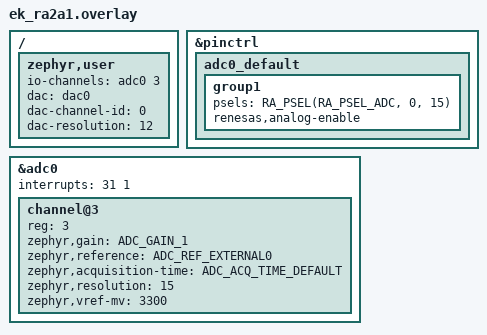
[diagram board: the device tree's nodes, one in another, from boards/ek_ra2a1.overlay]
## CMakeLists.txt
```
# SPDX-License-Identifier: Apache-2.0

cmake_minimum_required(VERSION 3.28.0)

find_package(Zephyr REQUIRED HINTS $ENV{ZEPHYR_BASE})
project(adc_accuracy)

target_sources(app PRIVATE src/main.c)
target_sources_ifdef(CONFIG_REFERENCE_VOLTAGE_TEST app PRIVATE src/ref_volt.c)
target_sources_ifdef(CONFIG_DAC_SOURCE_TEST app PRIVATE src/dac_source.c)
```

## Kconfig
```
# Copyright (c) 2023 Intel Corporation
# Copyright (c) 2025 Renesas Electronics Corporation
#
# SPDX-License-Identifier: Apache-2.0

mainmenu "ADC accuracy test"

source "Kconfig.zephyr"

# Workaround to have commas on function arguments
ZEPHYR_USER := zephyr,user

config DAC_SOURCE_TEST
	bool "Test using a DAC source"
	select DAC
	depends on $(dt_node_has_prop,/$(ZEPHYR_USER),dac)
	depends on $(dt_node_has_prop,/$(ZEPHYR_USER),dac-channel-id)
	depends on $(dt_node_has_prop,/$(ZEPHYR_USER),dac-resolution)

config REFERENCE_VOLTAGE_TEST
	bool "Test using a ref voltage source"
	depends on $(dt_node_has_prop,/$(ZEPHYR_USER),reference-mv)
	depends on $(dt_node_has_prop,/$(ZEPHYR_USER),expected-accuracy)

config NUMBER_OF_PASSES
	int "Number of passes"
	default 5

config TEST_ADC_CALIBRATE_REQUIRED
	bool "Require calibrate field in ADC test"
	default y if DT_HAS_RENESAS_RA_ADC16_ENABLED

if DAC_SOURCE_TEST

config DAC_BUFFER_NOT_SUPPORTED
	bool "DAC on board/SoC does not support output buffer mode"
	help
	  If this config is selected, the test will run with no output buffer enabled

endif # DAC_SOURCE_TEST
```

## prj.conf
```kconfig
CONFIG_ZTEST=y
CONFIG_ADC=y
```

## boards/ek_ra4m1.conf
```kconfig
# Copyright (c) 2025 Renesas Electronics Corporation
# SPDX-License-Identifier: Apache-2.0

CONFIG_DAC_BUFFER_NOT_SUPPORTED=y
```

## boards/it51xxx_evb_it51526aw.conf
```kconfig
# Copyright (c) 2026 ITE Corporation. All Rights Reserved.
# SPDX-License-Identifier: Apache-2.0

CONFIG_REFERENCE_VOLTAGE_TEST=y
```

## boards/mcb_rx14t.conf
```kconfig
CONFIG_REFERENCE_VOLTAGE_TEST=y
```

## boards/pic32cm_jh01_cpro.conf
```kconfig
#SPDX-FileCopyrightText: Copyright (c) 2026 Microchip Technology Inc.
#SPDX-License-Identifier: Apache-2.0

CONFIG_DAC=y
CONFIG_DAC_BUFFER_NOT_SUPPORTED=y
```

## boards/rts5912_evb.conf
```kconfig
# RTS5912 EVB ADC Accuracy Test Configuration
# Enable reference voltage test mode (using potentiometer as voltage source)
CONFIG_REFERENCE_VOLTAGE_TEST=y
```

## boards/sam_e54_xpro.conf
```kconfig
# Copyright (c) 2026 Microchip Technology Inc.
# SPDX-License-Identifier: Apache-2.0

CONFIG_DAC=y
CONFIG_DAC_BUFFER_NOT_SUPPORTED=y
```

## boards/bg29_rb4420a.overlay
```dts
/*
 * Copyright (c) 2025 Silicon Laboratories Inc.
 *
 * SPDX-License-Identifier: Apache-2.0
 */

#include "dt-bindings/adc/silabs-adc.h"

/ {
	zephyr,user {
		io-channels = <&adc0 4>;
		reference-mv = <(1500 / 4)>;
		expected-accuracy = <32>;
	};
};

&adc0 {
	#address-cells = <1>;
	#size-cells = <0>;
	status = "okay";

	channel@4 {
		reg = <4>;
		zephyr,gain = "ADC_GAIN_1";
		zephyr,reference = "ADC_REF_INTERNAL";
		zephyr,acquisition-time = <ADC_ACQ_TIME_DEFAULT>;
		zephyr,resolution = <12>;
		zephyr,input-positive = <IADC_INPUT_VBAT>;
	};
};
```

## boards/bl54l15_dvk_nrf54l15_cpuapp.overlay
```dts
/*
 * SPDX-License-Identifier: Apache-2.0
 *
 * Copyright (c) 2024 Nordic Semiconductor ASA
 * Copyright (c) 2025 Ezurio LLC
 */

/ {
	zephyr,user {
		io-channels = <&adc 0>;
		reference-mv = <1800>;
		expected-accuracy = <64>;
	};
};

&adc {
	#address-cells = <1>;
	#size-cells = <0>;

	channel@0 {
		reg = <0>;
		zephyr,gain = "ADC_GAIN_1_2";
		zephyr,reference = "ADC_REF_INTERNAL";
		zephyr,acquisition-time = <ADC_ACQ_TIME_DEFAULT>;
		zephyr,input-positive = <NRF_SAADC_AIN2>;
		zephyr,resolution = <14>;
	};
};
```

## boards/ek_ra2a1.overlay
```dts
/*
 * Copyright (c) 2024-2025 Renesas Electronics Corporation
 *
 * SPDX-License-Identifier: Apache-2.0
 */

/ {
	zephyr,user {
		io-channels = <&adc0 3>;
		dac = <&dac0>;
		dac-channel-id = <0>;
		dac-resolution = <12>;
	};
};

&pinctrl {
	adc0_default: adc0_default {
		group1 {
			/* input */
			psels = <RA_PSEL(RA_PSEL_ADC, 0, 15)>;
			renesas,analog-enable;
		};
	};
};

&adc0 {
	#address-cells = <1>;
	#size-cells = <0>;
	interrupts = <31 1>;
	interrupt-names = "scanend";
	status = "okay";

	/*
	 * Channel 3 is used in single ended mode, with 15 bit resolution
	 */
	channel@3 {
		reg = <3>;
		zephyr,gain = "ADC_GAIN_1";
		zephyr,reference = "ADC_REF_EXTERNAL0";
		zephyr,acquisition-time = <ADC_ACQ_TIME_DEFAULT>;
		zephyr,resolution = <15>;
		zephyr,vref-mv = <3300>;
	};
};
```

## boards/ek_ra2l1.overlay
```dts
/*
 * Copyright (c) 2025 Renesas Electronics Corporation
 *
 * SPDX-License-Identifier: Apache-2.0
 */

/ {
	zephyr,user {
		io-channels = <&adc0 0>;
		dac = <&dac0>;
		dac-channel-id = <0>;
		dac-resolution = <12>;
	};
};

&adc0 {
	#address-cells = <1>;
	#size-cells = <0>;
	status = "okay";

	channel@0 {
		reg = <0>;
		zephyr,gain = "ADC_GAIN_1";
		zephyr,reference = "ADC_REF_INTERNAL";
		zephyr,acquisition-time = <ADC_ACQ_TIME_DEFAULT>;
		zephyr,resolution = <12>;
	};
};
```

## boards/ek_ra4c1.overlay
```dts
/*
 * Copyright (c) 2025 Renesas Electronics Corporation
 *
 * SPDX-License-Identifier: Apache-2.0
 */

/ {
	zephyr,user {
		io-channels = <&adc0 0>;
		reference-mv = <3300>;
		expected-accuracy = <32>;
	};
};

&adc0 {
	#address-cells = <1>;
	#size-cells = <0>;
	status = "okay";

	channel@0 {
		reg = <0>;
		zephyr,gain = "ADC_GAIN_1";
		zephyr,reference = "ADC_REF_INTERNAL";
		zephyr,acquisition-time = <ADC_ACQ_TIME_DEFAULT>;
		zephyr,resolution = <12>;
		zephyr,vref-mv = <3300>;
	};
};
```

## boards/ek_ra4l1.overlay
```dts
/*
 * Copyright (c) 2025 Renesas Electronics Corporation
 *
 * SPDX-License-Identifier: Apache-2.0
 */

/ {
	zephyr,user {
		io-channels = <&adc0 1>;
		dac = <&dac0>;
		dac-channel-id = <0>;
		dac-resolution = <12>;
	};
};

&adc0 {
	#address-cells = <1>;
	#size-cells = <0>;
	status = "okay";

	channel@1 {
		reg = <1>;
		zephyr,gain = "ADC_GAIN_1";
		zephyr,reference = "ADC_REF_INTERNAL";
		zephyr,acquisition-time = <ADC_ACQ_TIME_DEFAULT>;
		zephyr,resolution = <12>;
	};
};
```

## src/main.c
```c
/*
 * Copyright (c) 2023 Intel Corporation
 *
 * SPDX-License-Identifier: Apache-2.0
 */

#include <zephyr/drivers/adc.h>
#include <zephyr/ztest.h>

#if DT_NODE_HAS_PROP(DT_PATH(zephyr_user), io_channels)
static const struct adc_dt_spec adc_channel = ADC_DT_SPEC_GET(DT_PATH(zephyr_user));
#else
#error "Unsupported board."
#endif

const struct adc_dt_spec *get_adc_channel(void)
{
	return &adc_channel;
}

static void *adc_setup(void)
{
	int ret;

	zassert_true(adc_is_ready_dt(&adc_channel), "ADC device is not ready");
	ret = adc_channel_setup_dt(&adc_channel);
	zassert_equal(ret, 0,
		"Setting up of the ADC channel failed with code %d", ret);

	return NULL;
}

ZTEST_SUITE(adc_accuracy_test, NULL, adc_setup, NULL, NULL, NULL);
```

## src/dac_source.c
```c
/*
 * Copyright (c) 2023 Intel Corporation
 *
 * SPDX-License-Identifier: Apache-2.0
 */

#include <zephyr/drivers/adc.h>
#include <zephyr/drivers/dac.h>
#include <zephyr/ztest.h>

#define DIV 2

#define DAC_DEVICE_NODE	DT_PROP(DT_PATH(zephyr_user), dac)

extern const struct adc_dt_spec *get_adc_channel(void);

static const struct dac_channel_cfg dac_ch_cfg = {
	.channel_id = DT_PROP(DT_PATH(zephyr_user), dac_channel_id),
	.resolution = DT_PROP(DT_PATH(zephyr_user), dac_resolution),
	.buffered = !IS_ENABLED(CONFIG_DAC_BUFFER_NOT_SUPPORTED),
};

static const struct device *init_dac(void)
{
	int ret;
	const struct device *const dac_dev = DEVICE_DT_GET(DAC_DEVICE_NODE);

	zassert_true(device_is_ready(dac_dev), "DAC device is not ready");

	ret = dac_channel_setup(dac_dev, &dac_ch_cfg);
	zassert_equal(ret, 0,
		      "Setting up of the first channel failed with code %d", ret);

	return dac_dev;
}

static int test_dac_to_adc(void)
{
	int ret, write_val;
	int32_t sample_buffer = 0;

	struct adc_sequence sequence = {
		.buffer      = &sample_buffer,
		.buffer_size = sizeof(sample_buffer),
#if CONFIG_TEST_ADC_CALIBRATE_REQUIRED
		.calibrate = true,
#endif
	};

	const struct device *dac_dev = init_dac();
	const struct adc_dt_spec *adc_channel = get_adc_channel();

	write_val = (1U << dac_ch_cfg.resolution) / DIV;

	ret = dac_write_value(dac_dev, DT_PROP(DT_PATH(zephyr_user), dac_channel_id), write_val);

	zassert_equal(ret, 0, "dac_write_value() failed with code %d", ret);

	k_sleep(K_MSEC(10));

	adc_sequence_init_dt(adc_channel, &sequence);
	ret = adc_read_dt(adc_channel, &sequence);

	zassert_equal(ret, 0, "adc_read_dt() failed with code %d", ret);
	zassert_within(sample_buffer,
			(1U << adc_channel->resolution) / DIV, 32,
			"Value %d read from ADC does not match expected range.",
			sample_buffer);

	return TC_PASS;
}

ZTEST(adc_accuracy_test, test_dac_to_adc)
{
	int i;

	for (i = 0; i < CONFIG_NUMBER_OF_PASSES; i++) {
		zassert_true(test_dac_to_adc() == TC_PASS);
	}
}
```

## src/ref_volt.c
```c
/*
 * Copyright (c) 2023 Intel Corporation
 *
 * SPDX-License-Identifier: Apache-2.0
 */

#include <zephyr/drivers/adc.h>
#include <zephyr/ztest.h>

#define REF_V DT_PROP(DT_PATH(zephyr_user), reference_mv)
#define EXP_ACC DT_PROP(DT_PATH(zephyr_user), expected_accuracy)

extern const struct adc_dt_spec *get_adc_channel(void);

static int test_ref_to_adc(void)
{
	int ret;
	int32_t sample_buffer = 0;

	struct adc_sequence sequence = {
		.buffer      = &sample_buffer,
		.buffer_size = sizeof(sample_buffer),
		.calibrate = true,
	};

	const struct adc_dt_spec *adc_channel = get_adc_channel();

	adc_sequence_init_dt(adc_channel, &sequence);

	ret = adc_read_dt(adc_channel, &sequence);
	zassert_equal(ret, 0, "adc_read_dt() failed with code %d", ret);

	ret = adc_raw_to_millivolts_dt(adc_channel, &sample_buffer);
	zassert_equal(ret, 0, "adc_raw_to_millivolts_dt() failed with code %d",
		      ret);
	zassert_within(sample_buffer, REF_V, EXP_ACC,
		"Value %d mV read from ADC does not match expected range (%d mV).",
		sample_buffer, REF_V);

	return TC_PASS;
}

ZTEST(adc_accuracy_test, test_ref_to_adc)
{
	int i;

	for (i = 0; i < CONFIG_NUMBER_OF_PASSES; i++) {
		zassert_true(test_ref_to_adc() == TC_PASS);
	}
}
```
